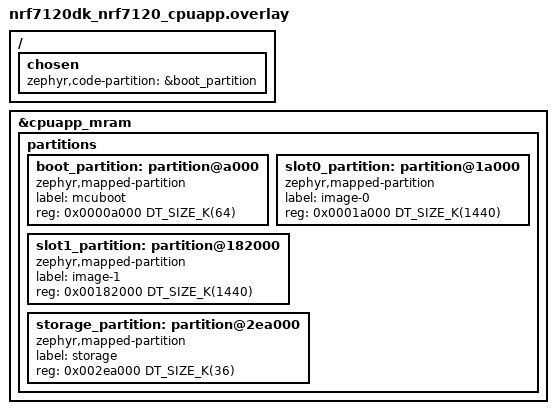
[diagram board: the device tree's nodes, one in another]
/*
 * Copyright (c) 2026 Nordic Semiconductor ASA
 *
 * SPDX-License-Identifier: LicenseRef-Nordic-5-Clause
 */

/delete-node/ &boot_partition;
/delete-node/ &slot0_partition;
/delete-node/ &slot1_partition;
/delete-node/ &storage_partition;

&cpuapp_mram {
	partitions {
		boot_partition: partition@a000 {
			compatible = "zephyr,mapped-partition";
			label = "mcuboot";
			reg = <0x0000a000 DT_SIZE_K(64)>;
		};

		slot0_partition: partition@1a000 {
			compatible = "zephyr,mapped-partition";
			label = "image-0";
			reg = <0x0001a000 DT_SIZE_K(1440)>;
		};

		slot1_partition: partition@182000 {
			compatible = "zephyr,mapped-partition";
			label = "image-1";
			reg = <0x00182000 DT_SIZE_K(1440)>;
		};

		storage_partition: partition@2ea000 {
			compatible = "zephyr,mapped-partition";
			label = "storage";
			reg = <0x002ea000 DT_SIZE_K(36)>;
		};
	};
};

/ {
	chosen {
		zephyr,code-partition = &boot_partition;
	};
};
